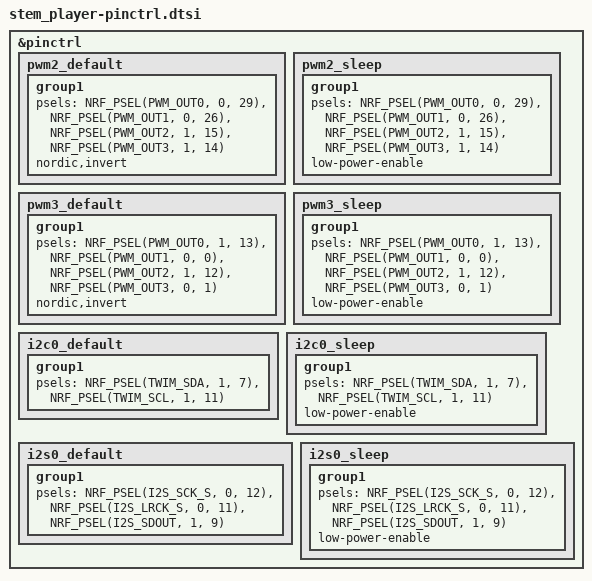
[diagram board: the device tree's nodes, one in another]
/*
 * Pin control for the Teenage Engineering SP-1 (looper firmware topology).
 * Pin map source: timknapen/SP-1-dev src/stemplayer_pins.h.
 *
 * I2S NOTE: unlike the sp1-midi BSP (nRF as I2S master), the looper runs the
 * board the way TE designed it — the 3.072 MHz oscillator drives SCK and the
 * CS42L42 codec masters LRCK, so the nRF's SCK/LRCK pins are INPUTS. The
 * _S PSEL variants configure them as such; SDOUT remains the nRF's output.
 */

&pinctrl {
	/* ---- LED rows (M1a) ----
	 * Pin order matches sp1_board.h's SP1_TRACK_LEDS / SP1_PLAY_LEDS exactly.
	 * Channel N here == index N there. Do not reorder one without the other.
	 * NOTE: TimK's stemplayer_pins.h lists the play LEDs in a DIFFERENT order;
	 * this follows the order sp1-tape-looper marks as hardware-verified. */
	pwm2_default: pwm2_default {          /* track LEDs: the model row */
		group1 {
			psels = <NRF_PSEL(PWM_OUT0, 0, 29)>,   /* T1 */
				<NRF_PSEL(PWM_OUT1, 0, 26)>,   /* T2 */
				<NRF_PSEL(PWM_OUT2, 1, 15)>,   /* T3 */
				<NRF_PSEL(PWM_OUT3, 1, 14)>;   /* T4 */
			nordic,invert;
		};
	};
	pwm2_sleep: pwm2_sleep {
		group1 {
			psels = <NRF_PSEL(PWM_OUT0, 0, 29)>,
				<NRF_PSEL(PWM_OUT1, 0, 26)>,
				<NRF_PSEL(PWM_OUT2, 1, 15)>,
				<NRF_PSEL(PWM_OUT3, 1, 14)>;
			low-power-enable;
		};
	};

	pwm3_default: pwm3_default {          /* play LEDs: the side row / VU */
		group1 {
			psels = <NRF_PSEL(PWM_OUT0, 1, 13)>,
				<NRF_PSEL(PWM_OUT1, 0, 0)>,
				<NRF_PSEL(PWM_OUT2, 1, 12)>,
				<NRF_PSEL(PWM_OUT3, 0, 1)>;
			nordic,invert;
		};
	};
	pwm3_sleep: pwm3_sleep {
		group1 {
			psels = <NRF_PSEL(PWM_OUT0, 1, 13)>,
				<NRF_PSEL(PWM_OUT1, 0, 0)>,
				<NRF_PSEL(PWM_OUT2, 1, 12)>,
				<NRF_PSEL(PWM_OUT3, 0, 1)>;
			low-power-enable;
		};
	};

	i2c0_default: i2c0_default {
		group1 {
			psels = <NRF_PSEL(TWIM_SDA, 1, 7)>,   /* P1.07 */
				<NRF_PSEL(TWIM_SCL, 1, 11)>;  /* P1.11 */
		};
	};
	i2c0_sleep: i2c0_sleep {
		group1 {
			psels = <NRF_PSEL(TWIM_SDA, 1, 7)>,
				<NRF_PSEL(TWIM_SCL, 1, 11)>;
			low-power-enable;
		};
	};

	i2s0_default: i2s0_default {
		group1 {
			psels = <NRF_PSEL(I2S_SCK_S, 0, 12)>,   /* P0.12 BCLK in (osc-driven) */
				<NRF_PSEL(I2S_LRCK_S, 0, 11)>,  /* P0.11 LRCK in (CS42L42 master) */
				<NRF_PSEL(I2S_SDOUT, 1, 9)>;    /* P1.09 audio data out */
		};
	};
	i2s0_sleep: i2s0_sleep {
		group1 {
			psels = <NRF_PSEL(I2S_SCK_S, 0, 12)>,
				<NRF_PSEL(I2S_LRCK_S, 0, 11)>,
				<NRF_PSEL(I2S_SDOUT, 1, 9)>;
			low-power-enable;
		};
	};
};
